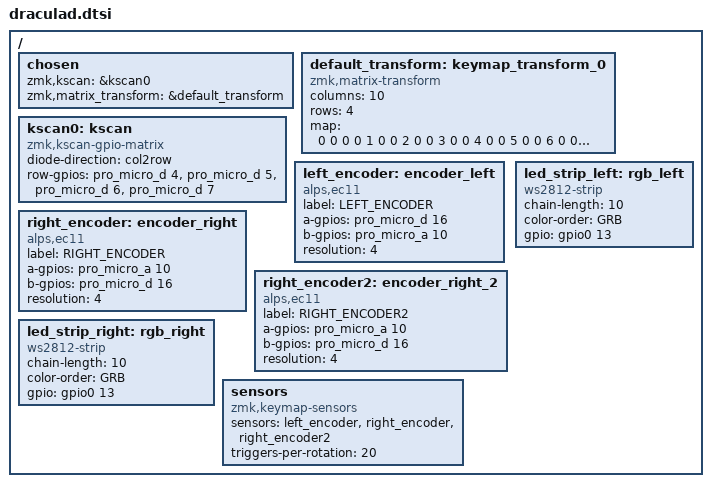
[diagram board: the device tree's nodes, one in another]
/*
 * Copyright (c) 2020 The ZMK Contributors
 *
 * SPDX-License-Identifier: MIT
 */

#include <dt-bindings/zmk/matrix_transform.h>

 / {
    chosen {
        zmk,kscan = &kscan0;
        zmk,matrix_transform = &default_transform;
    };

    default_transform: keymap_transform_0 {
        compatible = "zmk,matrix-transform";
        columns = <10>;
        rows = <4>;
      //  map = <
     //       RC(0,0) RC(0,1) RC(0,2) RC(0,3) RC(0,4)                         RC(0,5) RC(0,6) RC(0,7) RC(0,8) RC(0,9)
     //       RC(1,0) RC(1,1) RC(1,2) RC(1,3) RC(1,4)                         RC(1,5) RC(1,6) RC(1,7) RC(1,8) RC(1,9)
      //      RC(2,0) RC(2,1) RC(2,2) RC(2,3) RC(2,4) RC(3,1)         RC(3,8) RC(2,5) RC(2,6) RC(2,7) RC(2,8) RC(2,9)
     //                               RC(3,2) RC(3,3) RC(3,4)         RC(3,5) RC(3,6) RC(3,7)
     //   >;

map = <
    0 0 0  0 1 0  0 2 0  0 3 0  0 4 0          0 5 0  0 6 0  0 7 0  0 8 0  0 9 0
    1 0 0  1 1 0  1 2 0  1 3 0  1 4 0          1 5 0  1 6 0  1 7 0  1 8 0  1 9 0
    2 0 0  2 1 0  2 2 0  2 3 0  2 4 0  3 1 0   3 8 0  2 5 0  2 6 0  2 7 0  2 8 0  2 9 0
                  3 2 0  3 3 0  3 4 0          3 5 0  3 6 0  3 7 0
>;

    };

    kscan0: kscan {
        compatible = "zmk,kscan-gpio-matrix";
        diode-direction = "col2row";
        row-gpios = <&pro_micro_d 4 (GPIO_ACTIVE_HIGH | GPIO_PULL_DOWN)>,
                    <&pro_micro_d 5 (GPIO_ACTIVE_HIGH | GPIO_PULL_DOWN)>,
                    <&pro_micro_d 6 (GPIO_ACTIVE_HIGH | GPIO_PULL_DOWN)>,
                    <&pro_micro_d 7 (GPIO_ACTIVE_HIGH | GPIO_PULL_DOWN)>;
    };

    left_encoder: encoder_left {
            compatible = "alps,ec11";
            label = "LEFT_ENCODER";
            a-gpios = <&pro_micro_d 16 (GPIO_ACTIVE_HIGH | GPIO_PULL_UP)>;
            b-gpios = <&pro_micro_a 10 (GPIO_ACTIVE_HIGH | GPIO_PULL_UP)>;
            resolution = <4>;
        };

    right_encoder: encoder_right {
            compatible = "alps,ec11";
            label = "RIGHT_ENCODER";
            a-gpios = <&pro_micro_a 10 (GPIO_ACTIVE_HIGH | GPIO_PULL_UP)>;
            b-gpios = <&pro_micro_d 16 (GPIO_ACTIVE_HIGH | GPIO_PULL_UP)>;
            resolution = <4>;
    };    
right_encoder2: encoder_right_2 {
            compatible = "alps,ec11";
            label = "RIGHT_ENCODER2";
            a-gpios = <&pro_micro_a 10 (GPIO_ACTIVE_HIGH | GPIO_PULL_UP)>;
            b-gpios = <&pro_micro_d 16 (GPIO_ACTIVE_HIGH | GPIO_PULL_UP)>;
            resolution = <4>;
    };

    led_strip_left: rgb_left {
        compatible = "ws2812-strip";
        chain-length = <10>;
        color-order = "GRB";
        gpio = <&gpio0 13 GPIO_ACTIVE_HIGH>;
    };

    led_strip_right: rgb_right {
        compatible = "ws2812-strip";
        chain-length = <10>;
        color-order = "GRB";
        gpio = <&gpio0 13 GPIO_ACTIVE_HIGH>;
    };

    sensors {
        compatible = "zmk,keymap-sensors";
        sensors = <&left_encoder &right_encoder &right_encoder2>;
        triggers-per-rotation = <20>;
    };


};




